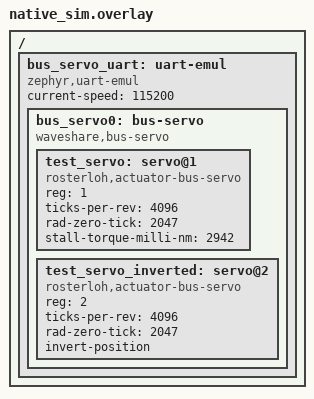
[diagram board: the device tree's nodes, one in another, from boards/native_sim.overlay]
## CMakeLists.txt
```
cmake_minimum_required(VERSION 3.20.0)

find_package(Zephyr REQUIRED HINTS $ENV{ZEPHYR_BASE})
project(test_bus_servo)

target_sources(app PRIVATE
    src/main.c
    src/fake_bus.c
    src/test_protocol.c
    src/test_feedback.c
)

zephyr_include_directories(./src)
zephyr_include_directories(${ZEPHYR_DRIVERS_REPO_ROOT}/drivers/bus_servo)
```

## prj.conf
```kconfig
CONFIG_ZTEST=y
CONFIG_SERIAL=y
CONFIG_EMUL=y
CONFIG_UART_EMUL=y
CONFIG_BUS_SERVO=y
CONFIG_BUS_SERVO_LOG_LEVEL_DBG=y
CONFIG_ACTUATOR=y
CONFIG_ACTUATOR_BUS_SERVO=y
```

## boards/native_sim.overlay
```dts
/ {
	bus_servo_uart: uart-emul {
		compatible = "zephyr,uart-emul";
		current-speed = <115200>;
		status = "okay";

		bus_servo0: bus-servo {
			compatible = "waveshare,bus-servo";
			status = "okay";
			#address-cells = <1>;
			#size-cells = <0>;

			/* Carries a stall torque, so effort is reported. */
			test_servo: servo@1 {
				compatible = "rosterloh,actuator-bus-servo";
				reg = <1>;
				ticks-per-rev = <4096>;
				rad-zero-tick = <2047>;
				stall-torque-milli-nm = <2942>;
			};

			/* Inverted and with no stall torque, covering both the sign flip
			 * and the path that leaves effort unreported. */
			test_servo_inverted: servo@2 {
				compatible = "rosterloh,actuator-bus-servo";
				reg = <2>;
				ticks-per-rev = <4096>;
				rad-zero-tick = <2047>;
				invert-position;
			};
		};
	};
};
```

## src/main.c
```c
#include <zephyr/ztest.h>
```

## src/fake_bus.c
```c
#include "fake_bus.h"

#include <string.h>
#include <zephyr/drivers/serial/uart_emul.h>
#include <zephyr/sys/util.h>
#include <zephyr/ztest.h>

static void tx_data_ready_cb(const struct device *dev, size_t size, void *user_data)
{
	struct fake_bus *bus = user_data;
	uint8_t buf[16];
	size_t remaining = sizeof(bus->last_tx) - bus->last_tx_len;
	size_t pending = size;

	while (pending > 0) {
		size_t chunk = MIN(pending, sizeof(buf));
		uint32_t got = uart_emul_get_tx_data(dev, buf, chunk);

		if (got == 0) {
			break;
		}

		size_t copy_len = MIN((size_t)got, remaining);

		if (copy_len > 0) {
			memcpy(bus->last_tx + bus->last_tx_len, buf, copy_len);
			bus->last_tx_len += copy_len;
			remaining -= copy_len;
		}
		zassert_equal(copy_len, (size_t)got, "fake bus TX capture overflow");
		pending -= got;
	}

	if (!bus->drop_response && bus->pending_rx_len > 0) {
		uint32_t written = uart_emul_put_rx_data(dev, bus->pending_rx, bus->pending_rx_len);

		zassert_equal(written, (uint32_t)bus->pending_rx_len,
			      "fake bus RX injection truncated");
		bus->pending_rx_len = 0;
	}
}

void fake_bus_init(struct fake_bus *bus)
{
	memset(bus, 0, sizeof(*bus));
}

void fake_bus_attach(struct fake_bus *bus, const struct device *uart_dev)
{
	bus->uart = uart_dev;
	uart_emul_callback_tx_data_ready_set(uart_dev, tx_data_ready_cb, bus);
}

void fake_bus_queue_rx(struct fake_bus *bus, const uint8_t *data, size_t len)
{
	if (bus->drop_response) {
		return;
	}

	zassert_true(len <= sizeof(bus->pending_rx), "fake bus RX injection too large");

	memcpy(bus->pending_rx, data, len);
	bus->pending_rx_len = len;
}
```

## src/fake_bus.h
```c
#ifndef TEST_BUS_SERVO_FAKE_BUS_H_
#define TEST_BUS_SERVO_FAKE_BUS_H_

#include <stddef.h>
#include <stdbool.h>
#include <stdint.h>
#include <zephyr/device.h>

struct fake_bus {
	uint8_t last_tx[64];
	size_t last_tx_len;
	uint8_t pending_rx[64];
	size_t pending_rx_len;
	const struct device *uart;
	bool drop_response;
};

void fake_bus_init(struct fake_bus *bus);
void fake_bus_attach(struct fake_bus *bus, const struct device *uart_dev);
void fake_bus_queue_rx(struct fake_bus *bus, const uint8_t *data, size_t len);

#endif /* TEST_BUS_SERVO_FAKE_BUS_H_ */
```

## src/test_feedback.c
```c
/*
 * Decode tests for the bus-servo actuator's present-state block.
 *
 * The block is read in one transaction and its fields are sign-magnitude with
 * the sign bit in a different place for speed (15) than for load (10). Decoding
 * either as two's complement turns a small negative rate into a large positive
 * one, which no build error catches and which looks plausible on a plot.
 */

#include <zephyr/actuator/actuator.h>
#include <zephyr/device.h>
#include <zephyr/devicetree.h>
#include <zephyr/drivers/uart.h>
#include <zephyr/sys/util.h>
#include <zephyr/ztest.h>
#include <drivers/bus_servo.h>

#include "fake_bus.h"

#define BUS_NODE   DT_NODELABEL(bus_servo0)
#define UART_NODE  DT_PARENT(BUS_NODE)
#define IFACE_NAME DEVICE_DT_NAME(BUS_NODE)

static const struct device *uart_dev = DEVICE_DT_GET(UART_NODE);
static const struct device *servo = DEVICE_DT_GET(DT_NODELABEL(test_servo));
static const struct device *servo_inv = DEVICE_DT_GET(DT_NODELABEL(test_servo_inverted));
static struct fake_bus bus;
static int iface;

/*
 * position    3071 ticks  -> +1024 from the 2047 zero, a quarter turn
 * speed     0x8064        -> sign bit 15 set, magnitude 100 ticks/s, so -100
 * load      0x05f4        -> sign bit 10 set, magnitude 500 per-mille, so -500
 * voltage   0x78          -> 12.0 V, not decoded (no actuator_feedback field)
 * temp      0x2d          -> 45 degC
 */
static const uint8_t present_block_id1[] = {
	0xff, 0xff, 0x01, 0x0a, 0x00, 0xff, 0x0b, 0x64, 0x80, 0xf4, 0x05, 0x78, 0x2d, 0x68,
};
static const uint8_t present_block_id2[] = {
	0xff, 0xff, 0x02, 0x0a, 0x00, 0xff, 0x0b, 0x64, 0x80, 0xf4, 0x05, 0x78, 0x2d, 0x67,
};

#define EXPECT_POSITION_RAD  1.5707963f
#define EXPECT_VELOCITY_RADS (-0.15339808f)
#define EXPECT_EFFORT_NM     (-1.471f)
#define TOLERANCE            1e-4f

static void before_each(void *fixture)
{
	ARG_UNUSED(fixture);
	struct bus_servo_iface_param param = {
		.rx_timeout_us = 50000,
		.serial = {.baud = 115200, .parity = UART_CFG_PARITY_NONE},
	};

	fake_bus_init(&bus);
	fake_bus_attach(&bus, uart_dev);
	iface = bus_servo_iface_get_by_name(IFACE_NAME);
	zassert_true(iface >= 0, "iface lookup failed: %d", iface);
	zassert_ok(bus_servo_init(iface, param), "bus_servo_init failed");
}

static void after_each(void *fixture)
{
	ARG_UNUSED(fixture);
	bus_servo_disable(iface);
}

ZTEST_SUITE(bus_servo_feedback, NULL, NULL, before_each, after_each, NULL);

ZTEST(bus_servo_feedback, test_reads_whole_block_in_one_transaction)
{
	struct actuator_feedback fb;

	fake_bus_queue_rx(&bus, present_block_id1, sizeof(present_block_id1));
	zassert_ok(actuator_read_feedback(servo, &fb));

	/* One READ of 8 bytes from reg 56, not five single-register reads. */
	const uint8_t expected_request[] = {
		0xff, 0xff, 0x01, 0x04, 0x02, 0x38, 0x08, 0xb8,
	};
	zassert_equal(bus.last_tx_len, sizeof(expected_request));
	zassert_mem_equal(bus.last_tx, expected_request, sizeof(expected_request));
}

ZTEST(bus_servo_feedback, test_decodes_sign_magnitude_fields)
{
	struct actuator_feedback fb;

	fake_bus_queue_rx(&bus, present_block_id1, sizeof(present_block_id1));
	zassert_ok(actuator_read_feedback(servo, &fb));

	zassert_true(fb.valid_mask & ACTUATOR_FB_POSITION);
	zassert_true(fb.valid_mask & ACTUATOR_FB_VELOCITY);
	zassert_true(fb.valid_mask & ACTUATOR_FB_TEMPERATURE);
	zassert_true(fb.valid_mask & ACTUATOR_FB_EFFORT);

	zassert_within(fb.position, EXPECT_POSITION_RAD, TOLERANCE, "position %f",
		       (double)fb.position);
	/* Two's-complement decoding would give +33380 ticks/s here, not -100. */
	zassert_within(fb.velocity, EXPECT_VELOCITY_RADS, TOLERANCE, "velocity %f",
		       (double)fb.velocity);
	/* Sign bit 10, not 15: reading this as bit 15 would give +1524 per-mille. */
	zassert_within(fb.effort, EXPECT_EFFORT_NM, TOLERANCE, "effort %f", (double)fb.effort);
	zassert_within(fb.temperature, 45.0f, TOLERANCE, "temperature %f", (double)fb.temperature);
}

ZTEST(bus_servo_feedback, test_invert_position_also_inverts_velocity)
{
	struct actuator_feedback fb;

	fake_bus_queue_rx(&bus, present_block_id2, sizeof(present_block_id2));
	zassert_ok(actuator_read_feedback(servo_inv, &fb));

	/* Velocity differentiates position, so it has to carry the same sign
	 * convention or the two disagree about which way the joint is going. */
	zassert_within(fb.position, -EXPECT_POSITION_RAD, TOLERANCE, "position %f",
		       (double)fb.position);
	zassert_within(fb.velocity, -EXPECT_VELOCITY_RADS, TOLERANCE, "velocity %f",
		       (double)fb.velocity);
}

ZTEST(bus_servo_feedback, test_effort_unreported_without_stall_torque)
{
	struct actuator_feedback fb;

	fake_bus_queue_rx(&bus, present_block_id2, sizeof(present_block_id2));
	zassert_ok(actuator_read_feedback(servo_inv, &fb));

	/* Load is per-mille of stall torque; with no stall torque configured the
	 * flag must stay clear rather than publishing a percentage as newton-metres. */
	zassert_false(fb.valid_mask & ACTUATOR_FB_EFFORT);
}
```

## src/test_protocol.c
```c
#include <zephyr/devicetree.h>
#include <zephyr/device.h>
#include <zephyr/drivers/uart.h>
#include <zephyr/sys/util.h>
#include <zephyr/ztest.h>
#include <drivers/bus_servo.h>

#include "fake_bus.h"

#define BUS_NODE   DT_NODELABEL(bus_servo0)
#define UART_NODE  DT_PARENT(BUS_NODE)
#define IFACE_NAME DEVICE_DT_NAME(BUS_NODE)

static const struct device *uart_dev = DEVICE_DT_GET(UART_NODE);
static struct fake_bus bus;
static int iface;

static void before_each(void *fixture)
{
	ARG_UNUSED(fixture);
	struct bus_servo_iface_param param = {
		.rx_timeout_us = 50000,
		.serial = {.baud = 115200, .parity = UART_CFG_PARITY_NONE},
	};

	fake_bus_init(&bus);
	fake_bus_attach(&bus, uart_dev);
	iface = bus_servo_iface_get_by_name(IFACE_NAME);
	zassert_true(iface >= 0, "iface lookup failed: %d", iface);
	zassert_ok(bus_servo_init(iface, param), "bus_servo_init failed");
}

static void after_each(void *fixture)
{
	ARG_UNUSED(fixture);
	bus_servo_disable(iface);
}

ZTEST_SUITE(bus_servo_protocol, NULL, NULL, before_each, after_each, NULL);

ZTEST(bus_servo_protocol, test_write_u16_frame_bytes)
{
	/* FF FF id len inst addr value_l value_h checksum */
	zassert_ok(bus_servo_write_u16(iface, 2, 0x2a, 0x07ff));

	const uint8_t expected[] = {
		0xff, 0xff, 0x02, 0x05, 0x03, 0x2a, 0xff, 0x07, 0xc5,
	};
	zassert_equal(bus.last_tx_len, sizeof(expected));
	zassert_mem_equal(bus.last_tx, expected, sizeof(expected));
}

ZTEST(bus_servo_protocol, test_write_position_ex_frame_bytes)
{
	zassert_ok(bus_servo_write_position_ex(iface, 2, 2047, 300, 20));

	/* write addr 41: accel, pos_l, pos_h, time_l, time_h, speed_l, speed_h */
	const uint8_t expected[] = {
		0xff, 0xff, 0x02, 0x0a, 0x03, 0x29, 0x14, 0xff, 0x07, 0x00, 0x00, 0x2c, 0x01, 0x80,
	};
	zassert_equal(bus.last_tx_len, sizeof(expected));
	zassert_mem_equal(bus.last_tx, expected, sizeof(expected));
}

ZTEST(bus_servo_protocol, test_sync_write_position_ex_frame_bytes)
{
	const uint8_t ids[] = {2, 1};
	const uint16_t pos[] = {2047, 1500};
	const uint16_t spd[] = {300, 250};
	const uint8_t acc[] = {20, 10};

	zassert_ok(bus_servo_sync_write_position_ex(iface, ids, pos, spd, acc, 2));

	const uint8_t expected[] = {
		0xff, 0xff, 0xfe, 0x14, 0x83, 0x29, 0x07, 0x02, 0x14, 0xff, 0x07, 0x00,
		0x00, 0x2c, 0x01, 0x01, 0x0a, 0xdc, 0x05, 0x00, 0x00, 0xfa, 0x00, 0x0b,
	};
	zassert_equal(bus.last_tx_len, sizeof(expected));
	zassert_mem_equal(bus.last_tx, expected, sizeof(expected));
}

ZTEST(bus_servo_protocol, test_sync_write_position_ex_rejects_invalid_args)
{
	const uint8_t ids[] = {1, 2, 3, 4, 5, 6, 7, 8};
	const uint16_t pos[ARRAY_SIZE(ids)] = {0};
	const uint16_t spd[ARRAY_SIZE(ids)] = {0};
	const uint8_t acc[ARRAY_SIZE(ids)] = {0};

	zassert_equal(bus_servo_sync_write_position_ex(iface, NULL, pos, spd, acc, 1), -EINVAL);
	zassert_equal(bus_servo_sync_write_position_ex(iface, ids, NULL, spd, acc, 1), -EINVAL);
	zassert_equal(bus_servo_sync_write_position_ex(iface, ids, pos, NULL, acc, 1), -EINVAL);
	zassert_equal(bus_servo_sync_write_position_ex(iface, ids, pos, spd, NULL, 1), -EINVAL);
	zassert_equal(bus_servo_sync_write_position_ex(iface, ids, pos, spd, acc, 0), -EINVAL);
	zassert_equal(bus_servo_sync_write_position_ex(iface, ids, pos, spd, acc, ARRAY_SIZE(ids)),
		      -EMSGSIZE);
}

ZTEST(bus_servo_protocol, test_read_u16_frame_and_response_parse)
{
	const uint8_t response[] = {
		0xff, 0xff, 0x01, 0x04, 0x00, 0x34, 0x12, 0xb4,
	};
	uint16_t value = 0;

	fake_bus_queue_rx(&bus, response, sizeof(response));
	zassert_ok(bus_servo_read_u16(iface, 1, 0x38, &value));

	const uint8_t expected_request[] = {
		0xff, 0xff, 0x01, 0x04, 0x02, 0x38, 0x02, 0xbe,
	};
	zassert_equal(value, 0x1234);
	zassert_equal(bus.last_tx_len, sizeof(expected_request));
	zassert_mem_equal(bus.last_tx, expected_request, sizeof(expected_request));
}

ZTEST(bus_servo_protocol, test_read_u16_rejects_extra_response_bytes)
{
	const uint8_t response[] = {
		0xff, 0xff, 0x01, 0x05, 0x00, 0x34, 0x12, 0x99, 0x1a,
	};
	uint16_t value = 0;

	fake_bus_queue_rx(&bus, response, sizeof(response));
	zassert_equal(bus_servo_read_u16(iface, 1, 0x38, &value), -EBADMSG);
}

ZTEST(bus_servo_protocol, test_timeout_returns_etimedout)
{
	uint16_t value = 0;

	bus.drop_response = true;
	zassert_equal(bus_servo_read_u16(iface, 1, 0x38, &value), -ETIMEDOUT);
}
```
